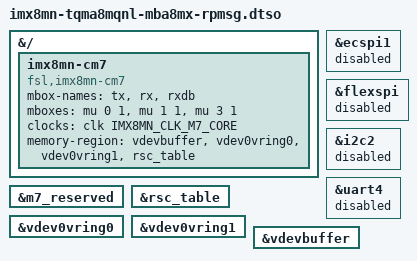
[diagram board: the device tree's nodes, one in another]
// SPDX-License-Identifier: (GPL-2.0-or-later OR MIT)
/*
 * Copyright (c) 2021-2024 TQ-Systems GmbH <linux@ew.tq-group.com>,
 * D-82229 Seefeld, Germany.
 * Author: Alexander Stein
 */

/dts-v1/;
/plugin/;

#include <dt-bindings/clock/imx8mn-clock.h>

&{/} {
	imx8mn-cm7 {
		compatible = "fsl,imx8mn-cm7";
		mbox-names = "tx", "rx", "rxdb";
		mboxes = <&mu 0 1
			  &mu 1 1
			  &mu 3 1>;
		clocks = <&clk IMX8MN_CLK_M7_CORE>;
		memory-region = <&vdevbuffer>, <&vdev0vring0>,
				<&vdev0vring1>, <&rsc_table>;
	};
};

/*
 * ATTENTION: M7 may use IPs like below
 * UART4, I2C2, ECSPI2, FLEXSPI
 * if access to more hardware is needed, keep in mind to disable it to prevent
 * system lockup and other things. Also resource partitioning using RDC
 * should be implemented. See TF-A implementation.
 */

&ecspi1 {
	status = "disabled";
};

&flexspi {
	status = "disabled";
};

&i2c2 {
	status = "disabled";
};

&m7_reserved {
	status = "okay";
};

&rsc_table {
	status = "okay";
};

&uart4 {
	status = "disabled";
};

&vdev0vring0 {
	status = "okay";
};

&vdev0vring1 {
	status = "okay";
};

&vdevbuffer {
	status = "okay";
};
